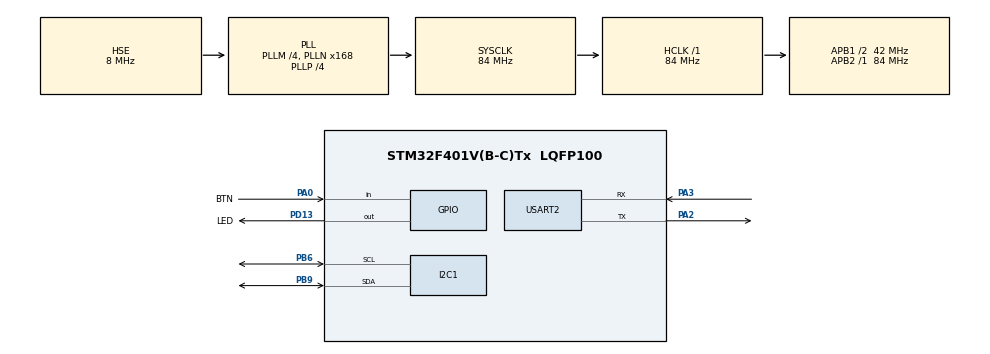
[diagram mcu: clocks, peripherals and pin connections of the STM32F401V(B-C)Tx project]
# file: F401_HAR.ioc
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I2C1.I2C_Mode=I2C_Fast
Mcu.Family=STM32F4
Mcu.Name=STM32F401V(B-C)Tx
Mcu.Package=LQFP100
NVIC.PriorityGroup=NVIC_PRIORITYGROUP_4
NVIC.TIM1_UP_TIM10_IRQn=true\:0\:0\:false\:false\:true\:true\:true\:true
PA0-WKUP.GPIO_Label=BTN
PA0-WKUP.Signal=GPIO_Input
PA2.Mode=Asynchronous
PA2.Signal=USART2_TX
PA3.Mode=Asynchronous
PA3.Signal=USART2_RX
PB6.Mode=I2C
PB6.Signal=I2C1_SCL
PB9.Mode=I2C
PB9.Signal=I2C1_SDA
PD13.GPIO_Label=LED
PD13.Signal=GPIO_Output
PH0\ -\ OSC_IN.Mode=HSE-External-Oscillator
PH0\ -\ OSC_IN.Signal=RCC_OSC_IN
PH1\ -\ OSC_OUT.Mode=HSE-External-Oscillator
PH1\ -\ OSC_OUT.Signal=RCC_OSC_OUT
ProjectManager.HeapSize=0x800
ProjectManager.StackSize=0x800
ProjectManager.TargetToolchain=STM32CubeIDE
RCC.48MHZClocksFreq_Value=48000000
RCC.AHBFreq_Value=84000000
RCC.APB1CLKDivider=RCC_HCLK_DIV2
RCC.APB1Freq_Value=42000000
RCC.APB1TimFreq_Value=84000000
RCC.APB2Freq_Value=84000000
RCC.APB2TimFreq_Value=84000000
RCC.CortexFreq_Value=84000000
RCC.HCLKFreq_Value=84000000
RCC.HSE_VALUE=8000000
RCC.HSI_VALUE=16000000
RCC.LSE_VALUE=32768
RCC.PLLM=4
RCC.PLLN=168
RCC.PLLP=RCC_PLLP_DIV4
RCC.PLLQ=7
RCC.PLLSourceVirtual=RCC_PLLSOURCE_HSE
RCC.SYSCLKFreq_VALUE=84000000
RCC.SYSCLKSource=RCC_SYSCLKSOURCE_PLLCLK
RCC.VCOOutputFreq_Value=336000000
STMicroelectronics.X-CUBE-AI.7.1.0.ActivationBufferSizeList=25680
STMicroelectronics.X-CUBE-AI.7.1.0.ActivationBuffers=pool0
STMicroelectronics.X-CUBE-AI.7.1.0.ActivationNames=pool0
STMicroelectronics.X-CUBE-AI.7.1.0.ActivationSizes=AI_NETWORK_HAR_DATA_ACTIVATION_1_SIZE
STMicroelectronics.X-CUBE-AI.7.1.0.ApplicationCcDeviceJjApplication=ApplicationTemplate
STMicroelectronics.X-CUBE-AI.7.1.0.HeapSize=0x800
STMicroelectronics.X-CUBE-AI.7.1.0.InternalRamActivationBufferMaxSize=AI_NETWORK_HAR_DATA_ACTIVATIONS_SIZE
STMicroelectronics.X-CUBE-AI.7.1.0.LatestDirectoryUsed-6c94691040f41782f5bb4c00cd82cff836ac5d21fc54a49d0988b4e9b517c7a5=F\:\\opensource_proj\\HAR-CNN-Keras-master
STMicroelectronics.X-CUBE-AI.7.1.0.MaximumNumberOfInputLayer=1
STMicroelectronics.X-CUBE-AI.7.1.0.MaximumNumberOfOutputLayer=1
STMicroelectronics.X-CUBE-AI.7.1.0.MaximumSizeOfInputLayer=AI_NETWORK_HAR_IN_1_SIZE_BYTES
STMicroelectronics.X-CUBE-AI.7.1.0.MaximumSizeOfOutputLayer=AI_NETWORK_HAR_OUT_1_SIZE_BYTES
STMicroelectronics.X-CUBE-AI.7.1.0.ModelActualCompression-6c94691040f41782f5bb4c00cd82cff836ac5d21fc54a49d0988b4e9b517c7a5=7.27
STMicroelectronics.X-CUBE-AI.7.1.0.ModelCompression-6c94691040f41782f5bb4c00cd82cff836ac5d21fc54a49d0988b4e9b517c7a5=8
STMicroelectronics.X-CUBE-AI.7.1.0.ModelFlashOccupation-6c94691040f41782f5bb4c00cd82cff836ac5d21fc54a49d0988b4e9b517c7a5=201304
STMicroelectronics.X-CUBE-AI.7.1.0.ModelHashList=6c94691040f41782f5bb4c00cd82cff836ac5d21fc54a49d0988b4e9b517c7a5
STMicroelectronics.X-CUBE-AI.7.1.0.ModelKind-6c94691040f41782f5bb4c00cd82cff836ac5d21fc54a49d0988b4e9b517c7a5=KERAS
STMicroelectronics.X-CUBE-AI.7.1.0.ModelMacc-6c94691040f41782f5bb4c00cd82cff836ac5d21fc54a49d0988b4e9b517c7a5=501856
STMicroelectronics.X-CUBE-AI.7.1.0.ModelName-6c94691040f41782f5bb4c00cd82cff836ac5d21fc54a49d0988b4e9b517c7a5=network_har
STMicroelectronics.X-CUBE-AI.7.1.0.ModelNameList=network_har
STMicroelectronics.X-CUBE-AI.7.1.0.ModelRamOccupation-6c94691040f41782f5bb4c00cd82cff836ac5d21fc54a49d0988b4e9b517c7a5=25680
STMicroelectronics.X-CUBE-AI.7.1.0.ModelStructureFile-6c94691040f41782f5bb4c00cd82cff836ac5d21fc54a49d0988b4e9b517c7a5=F\:\\opensource_proj\\HAR-CNN-Keras-master\\model.h5
STMicroelectronics.X-CUBE-AI.7.1.0.ModelType-6c94691040f41782f5bb4c00cd82cff836ac5d21fc54a49d0988b4e9b517c7a5=Saved model
STMicroelectronics.X-CUBE-AI.7.1.0.ReadyForCodeGeneration=true
STMicroelectronics.X-CUBE-AI.7.1.0.StackSize=0x800
STMicroelectronics.X-CUBE-AI.7.1.0.ValidationInputFile-6c94691040f41782f5bb4c00cd82cff836ac5d21fc54a49d0988b4e9b517c7a5=F\:\\opensource_proj\\HAR-CNN-Keras-master\\testx.csv
STMicroelectronics.X-CUBE-AI.7.1.0.ValidationInputFileHistory-6c94691040f41782f5bb4c00cd82cff836ac5d21fc54a49d0988b4e9b517c7a5=F\:\\opensource_proj\\HAR-CNN-Keras-master\\testx.csv
STMicroelectronics.X-CUBE-AI.7.1.0.ValidationOutputFile-6c94691040f41782f5bb4c00cd82cff836ac5d21fc54a49d0988b4e9b517c7a5=F\:\\opensource_proj\\HAR-CNN-Keras-master\\testy.csv
STMicroelectronics.X-CUBE-AI.7.1.0.ValidationOutputFileHistory-6c94691040f41782f5bb4c00cd82cff836ac5d21fc54a49d0988b4e9b517c7a5=F\:\\opensource_proj\\HAR-CNN-Keras-master\\testy.csv
STMicroelectronics.X-CUBE-AI.7.1.0.WorkingBufferStartAddrList=0xFFFFFFFF
STMicroelectronics.X-CUBE-AI.7.1.0.XAaCUBEAaAICcArtificialOoIntelligenceJjCore=true
TIM1.Period=500-1
TIM1.Prescaler=8400-1
USART2.VirtualMode=VM_ASYNC
VP_CRC_VS_CRC.Mode=CRC_Activate
VP_STMicroelectronics.X-CUBE-AI_VS_ArtificialOoIntelligenceJjXAaCUBEAaAI_7.1.0.Mode=ArtificialOoIntelligenceJjXAaCUBEAaAI
VP_STMicroelectronics.X-CUBE-AI_VS_DeviceJjApplication_7.1.0.Mode=DeviceJjApplication
VP_TIM1_VS_ClockSourceINT.Mode=Internal
board=custom

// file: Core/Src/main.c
/* USER CODE BEGIN Header */
/**
  ******************************************************************************
  * @file           : main.c
  * @brief          : Main program body
  ******************************************************************************
  * @attention
  *
  * Copyright (c) 2022 STMicroelectronics.
  * All rights reserved.
  *
  * This software is licensed under terms that can be found in the LICENSE file
  * in the root directory of this software component.
  * If no LICENSE file comes with this software, it is provided AS-IS.
  *
  ******************************************************************************
  */
/* USER CODE END Header */
#include "main.h"
#include "crc.h"
#include "i2c.h"
#include "tim.h"
#include "usart.h"
#include "gpio.h"
#include "app_x-cube-ai.h"

void SystemClock_Config(void);

int main(void)
{

  /* MCU Configuration--------------------------------------------------------*/

  /* Reset of all peripherals, Initializes the Flash interface and the Systick. */
  HAL_Init();

  /* Configure the system clock */
  SystemClock_Config();

  /* Initialize all configured peripherals */
  MX_GPIO_Init();
  MX_CRC_Init();
  MX_USART2_UART_Init();
  MX_I2C1_Init();
  MX_TIM1_Init();
  MX_X_CUBE_AI_Init();
  /* USER CODE BEGIN 2 */
  LSM303DLHC_Init();
  HAL_TIM_Base_Start_IT(&htim1);
  /* USER CODE END 2 */

  /* Infinite loop */
  while (1)
  {

  MX_X_CUBE_AI_Process();
  }
}

void SystemClock_Config(void)
{
  RCC_OscInitTypeDef RCC_OscInitStruct = {0};
  RCC_ClkInitTypeDef RCC_ClkInitStruct = {0};

  /** Configure the main internal regulator output voltage
  */
  __HAL_RCC_PWR_CLK_ENABLE();
  __HAL_PWR_VOLTAGESCALING_CONFIG(PWR_REGULATOR_VOLTAGE_SCALE2);

  /** Initializes the RCC Oscillators according to the specified parameters
  * in the RCC_OscInitTypeDef structure.
  */
  RCC_OscInitStruct.OscillatorType = RCC_OSCILLATORTYPE_HSE;
  RCC_OscInitStruct.HSEState = RCC_HSE_ON;
  RCC_OscInitStruct.PLL.PLLState = RCC_PLL_ON;
  RCC_OscInitStruct.PLL.PLLSource = RCC_PLLSOURCE_HSE;
  RCC_OscInitStruct.PLL.PLLM = 4;
  RCC_OscInitStruct.PLL.PLLN = 168;
  RCC_OscInitStruct.PLL.PLLP = RCC_PLLP_DIV4;
  RCC_OscInitStruct.PLL.PLLQ = 7;
  if (HAL_RCC_OscConfig(&RCC_OscInitStruct) != HAL_OK)
  {
    Error_Handler();
  }

  /** Initializes the CPU, AHB and APB buses clocks
  */
  RCC_ClkInitStruct.ClockType = RCC_CLOCKTYPE_HCLK|RCC_CLOCKTYPE_SYSCLK
                              |RCC_CLOCKTYPE_PCLK1|RCC_CLOCKTYPE_PCLK2;
  RCC_ClkInitStruct.SYSCLKSource = RCC_SYSCLKSOURCE_PLLCLK;
  RCC_ClkInitStruct.AHBCLKDivider = RCC_SYSCLK_DIV1;
  RCC_ClkInitStruct.APB1CLKDivider = RCC_HCLK_DIV2;
  RCC_ClkInitStruct.APB2CLKDivider = RCC_HCLK_DIV1;

  if (HAL_RCC_ClockConfig(&RCC_ClkInitStruct, FLASH_LATENCY_2) != HAL_OK)
  {
    Error_Handler();
  }
}

void Error_Handler(void)
{
  __disable_irq();
  while (1)
  {
  }
}
